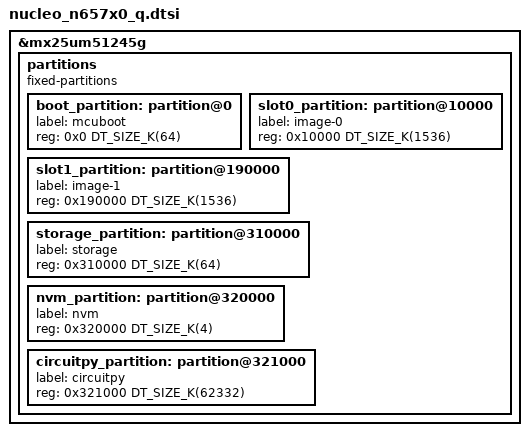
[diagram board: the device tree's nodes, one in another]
&mx25um51245g {
	partitions {
		compatible = "fixed-partitions";
		#address-cells = <1>;
		#size-cells = <1>;

		boot_partition: partition@0 {
			label = "mcuboot";
			reg = <0x0 DT_SIZE_K(64)>;
		};

		slot0_partition: partition@10000 {
			label = "image-0";
			reg = <0x10000 DT_SIZE_K(1536)>;
		};

		slot1_partition: partition@190000 {
			label = "image-1";
			reg = <0x190000 DT_SIZE_K(1536)>;
		};

		storage_partition: partition@310000 {
			label = "storage";
			reg = <0x310000 DT_SIZE_K(64)>;
		};

		nvm_partition: partition@320000 {
			label = "nvm";
			reg = <0x320000 DT_SIZE_K(4)>;
		};

		circuitpy_partition: partition@321000 {
			label = "circuitpy";
			reg = <0x321000 DT_SIZE_K(62332)>;
		};
	};
};
